VERSION "Infotainment_CAN_v1.0"

NS_ :

BS_:

BU_: SIL_TEST_CTRL INFOTAINMENT_GW IVI_GW NAV_CONTEXT_MGR CLU_HMI_CTRL CLUSTER_BASE_CTRL Vector__XXX

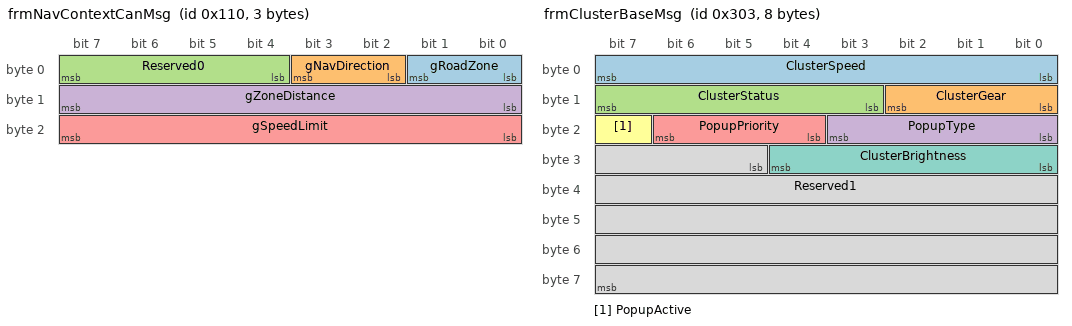
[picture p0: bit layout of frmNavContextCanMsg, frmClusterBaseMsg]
BO_ 272 frmNavContextCanMsg: 3 SIL_TEST_CTRL
 SG_ gRoadZone     : 0|2@1+ (1,0) [0|3]    "" INFOTAINMENT_GW,NAV_CONTEXT_MGR
 SG_ gNavDirection : 2|2@1+ (1,0) [0|3]    "" INFOTAINMENT_GW,NAV_CONTEXT_MGR
 SG_ Reserved0     : 4|4@1+ (1,0) [0|0]    "" Vector__XXX
 SG_ gZoneDistance : 8|8@1+ (1,0) [0|255]  "m" INFOTAINMENT_GW,NAV_CONTEXT_MGR
 SG_ gSpeedLimit   : 16|8@1+ (1,0) [0|255] "km/h" INFOTAINMENT_GW,NAV_CONTEXT_MGR

BO_ 544 frmClusterWarningMsg: 1 IVI_GW
 SG_ WarningTextCode : 0|8@1+ (1,0) [0|255] "" CLU_HMI_CTRL

BO_ 771 frmClusterBaseMsg: 8 IVI_GW
 SG_ ClusterSpeed      : 0|8@1+ (1,0) [0|255] "km/h" CLUSTER_BASE_CTRL
 SG_ ClusterGear       : 8|3@1+ (1,0) [0|7]   "" CLUSTER_BASE_CTRL
 SG_ ClusterStatus     : 11|5@1+ (1,0) [0|31] "" CLUSTER_BASE_CTRL
 SG_ PopupType         : 16|4@1+ (1,0) [0|15] "" CLU_HMI_CTRL
 SG_ PopupPriority     : 20|3@1+ (1,0) [0|7]  "" CLU_HMI_CTRL
 SG_ PopupActive       : 23|1@1+ (1,0) [0|1]  "" CLU_HMI_CTRL
 SG_ ClusterBrightness : 24|5@1+ (1,0) [0|31] "" CLUSTER_BASE_CTRL
 SG_ Reserved1         : 29|35@1+ (1,0) [0|0] "" Vector__XXX

CM_ BO_ 272 "Flow_003 navigation context input.";
CM_ BO_ 544 "Flow_008 cluster warning output.";
CM_ BO_ 771 "Comm_104 baseline cluster aggregate message (Req_109).";

BA_DEF_ BO_ "GenMsgCycleTime" INT 0 10000;
BA_DEF_DEF_ "GenMsgCycleTime" 0;
BA_ "GenMsgCycleTime" BO_ 272 100;
BA_ "GenMsgCycleTime" BO_ 544 50;
BA_ "GenMsgCycleTime" BO_ 771 50;

  0 "Normal"
  1 "SchoolZone"
  2 "Highway"
  3 "Guide" ;

  0 "None"
  1 "Left"
  2 "Right"
  3 "Other" ;
